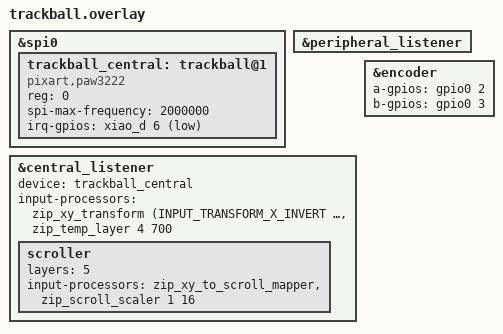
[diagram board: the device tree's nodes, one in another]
&spi0 {
    status = "okay";

    trackball_central: trackball@1 {
        status = "okay";
        compatible = "pixart,paw3222";
        reg = <0>;
        spi-max-frequency = <2000000>;
        irq-gpios = <&xiao_d 6 (GPIO_ACTIVE_LOW | GPIO_PULL_UP)>;
    };
};

// ペリフェラル（split経由）のリスナーを有効化
&peripheral_listener {
    status = "okay";
};

// セントラルのリスナーを有効化し、deviceを紐付け
&central_listener {
    status = "okay";
    device = <&trackball_central>;
    input-processors = 
        <&zip_xy_transform (INPUT_TRANSFORM_X_INVERT | INPUT_TRANSFORM_Y_INVERT)>,
        <&zip_temp_layer 4 700>;

    scroller {
        layers = <5>;
        input-processors = 
            <&zip_xy_to_scroll_mapper>,
            <&zip_scroll_scaler 1 16>;
    };
};

// ZMKの仕様上、ペリフェラルからのセンサーイベントを受け取るにはセントラル側でもセンサーが有効に初期化される必要がある。
// 右手のトラックボールと物理ピンが競合せず、かつ割り込みが機能する有効な空きピン(gpio0 2, 3)を割り当ててエンコーダを有効化する。
&encoder {
    status = "okay";
    a-gpios = <&gpio0 2 (GPIO_ACTIVE_HIGH | GPIO_PULL_UP)>;
    b-gpios = <&gpio0 3 (GPIO_ACTIVE_HIGH | GPIO_PULL_UP)>;
};
